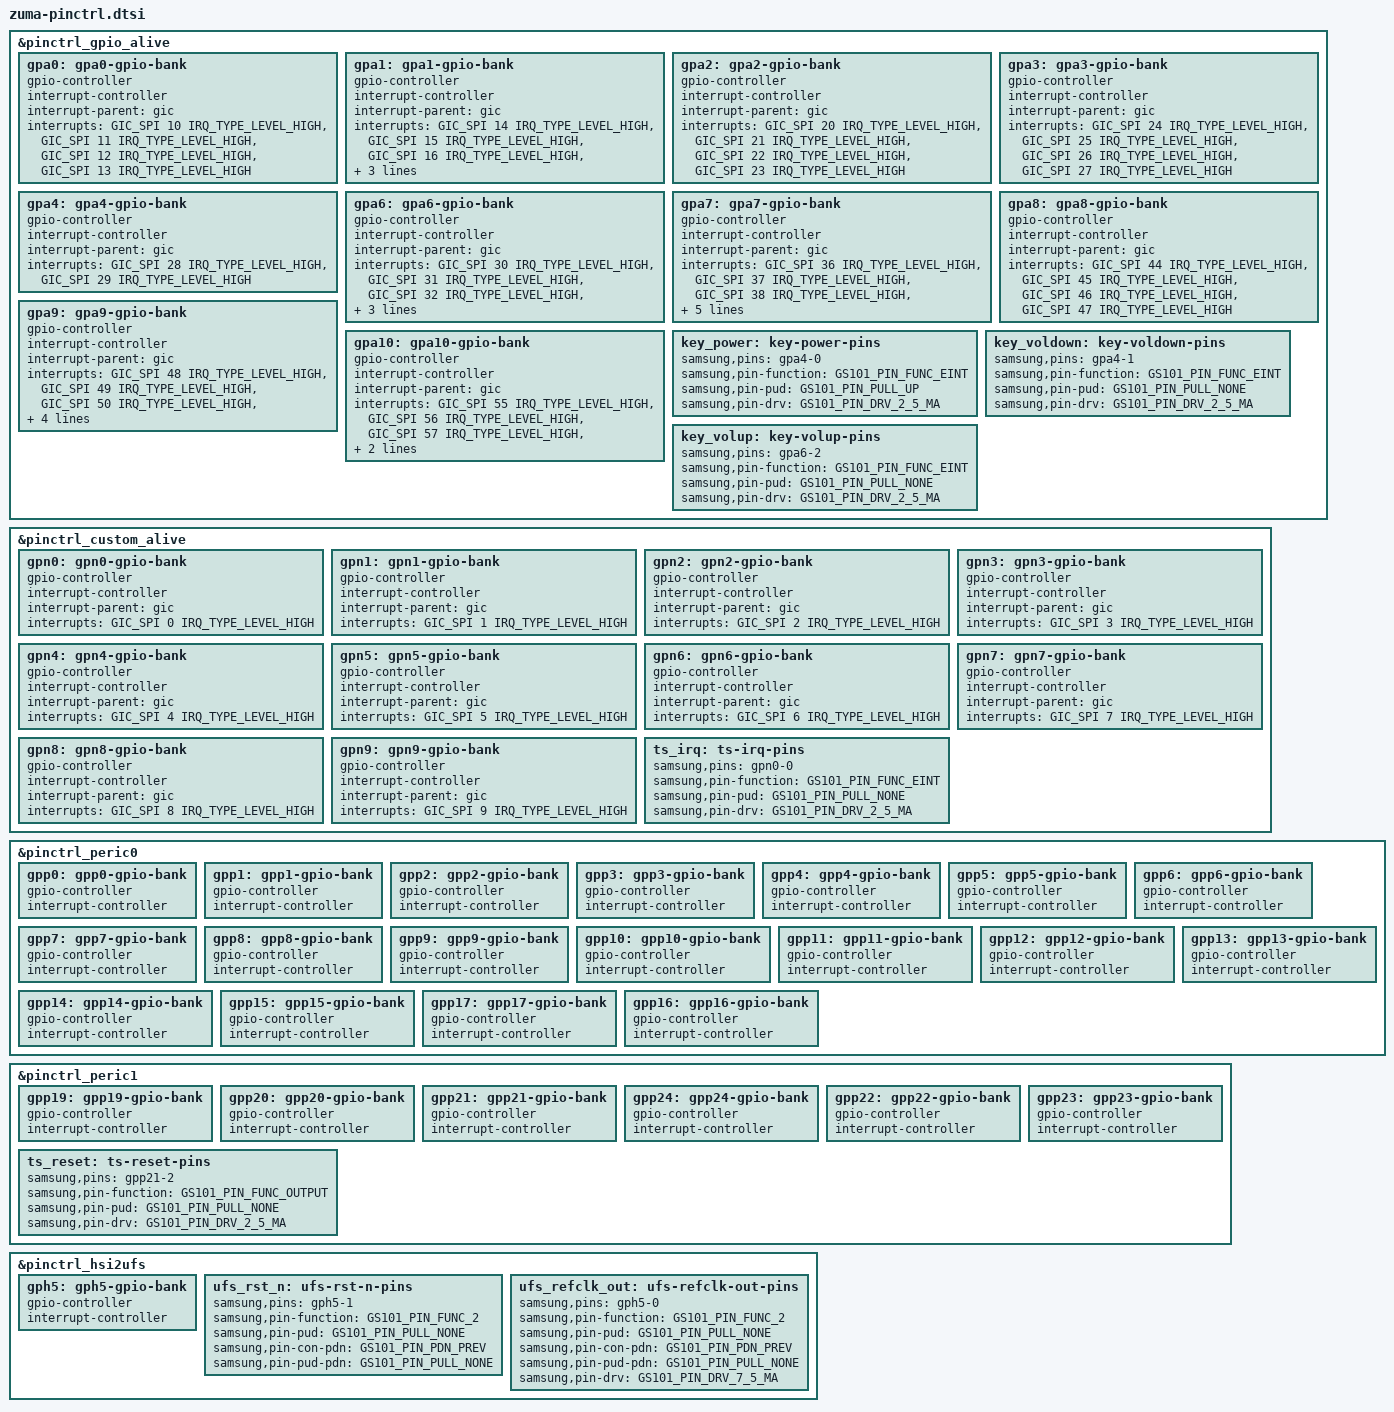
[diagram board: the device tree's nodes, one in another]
// SPDX-License-Identifier: GPL-2.0-only
/*
 * zuma (Tensor G3) pin banks and groups.
 *
 * Copyright 2020-2023 Google LLC
 */

#include "gs101-pinctrl.h"

&pinctrl_gpio_alive {
	gpa0: gpa0-gpio-bank {
		gpio-controller;
		#gpio-cells = <2>;
		interrupt-controller;
		#interrupt-cells = <2>;
		interrupt-parent = <&gic>;
		interrupts = <GIC_SPI 10 IRQ_TYPE_LEVEL_HIGH>,
			     <GIC_SPI 11 IRQ_TYPE_LEVEL_HIGH>,
			     <GIC_SPI 12 IRQ_TYPE_LEVEL_HIGH>,
			     <GIC_SPI 13 IRQ_TYPE_LEVEL_HIGH>;
	};

	gpa1: gpa1-gpio-bank {
		gpio-controller;
		#gpio-cells = <2>;
		interrupt-controller;
		#interrupt-cells = <2>;
		interrupt-parent = <&gic>;
		interrupts = <GIC_SPI 14 IRQ_TYPE_LEVEL_HIGH>,
			     <GIC_SPI 15 IRQ_TYPE_LEVEL_HIGH>,
			     <GIC_SPI 16 IRQ_TYPE_LEVEL_HIGH>,
			     <GIC_SPI 17 IRQ_TYPE_LEVEL_HIGH>,
			     <GIC_SPI 18 IRQ_TYPE_LEVEL_HIGH>,
			     <GIC_SPI 19 IRQ_TYPE_LEVEL_HIGH>;
	};

	gpa2: gpa2-gpio-bank {
		gpio-controller;
		#gpio-cells = <2>;
		interrupt-controller;
		#interrupt-cells = <2>;
		interrupt-parent = <&gic>;
		interrupts = <GIC_SPI 20 IRQ_TYPE_LEVEL_HIGH>,
			     <GIC_SPI 21 IRQ_TYPE_LEVEL_HIGH>,
			     <GIC_SPI 22 IRQ_TYPE_LEVEL_HIGH>,
			     <GIC_SPI 23 IRQ_TYPE_LEVEL_HIGH>;
	};

	gpa3: gpa3-gpio-bank {
		gpio-controller;
		#gpio-cells = <2>;
		interrupt-controller;
		#interrupt-cells = <2>;
		interrupt-parent = <&gic>;
		interrupts = <GIC_SPI 24 IRQ_TYPE_LEVEL_HIGH>,
			     <GIC_SPI 25 IRQ_TYPE_LEVEL_HIGH>,
			     <GIC_SPI 26 IRQ_TYPE_LEVEL_HIGH>,
			     <GIC_SPI 27 IRQ_TYPE_LEVEL_HIGH>;
	};

	gpa4: gpa4-gpio-bank {
		gpio-controller;
		#gpio-cells = <2>;
		interrupt-controller;
		#interrupt-cells = <2>;
		interrupt-parent = <&gic>;
		interrupts = <GIC_SPI 28 IRQ_TYPE_LEVEL_HIGH>,
			     <GIC_SPI 29 IRQ_TYPE_LEVEL_HIGH>;
	};

	gpa6: gpa6-gpio-bank {
		gpio-controller;
		#gpio-cells = <2>;
		interrupt-controller;
		#interrupt-cells = <2>;
		interrupt-parent = <&gic>;
		interrupts = <GIC_SPI 30 IRQ_TYPE_LEVEL_HIGH>,
			     <GIC_SPI 31 IRQ_TYPE_LEVEL_HIGH>,
			     <GIC_SPI 32 IRQ_TYPE_LEVEL_HIGH>,
			     <GIC_SPI 33 IRQ_TYPE_LEVEL_HIGH>,
			     <GIC_SPI 34 IRQ_TYPE_LEVEL_HIGH>,
			     <GIC_SPI 35 IRQ_TYPE_LEVEL_HIGH>;
	};

	gpa7: gpa7-gpio-bank {
		gpio-controller;
		#gpio-cells = <2>;
		interrupt-controller;
		#interrupt-cells = <2>;
		interrupt-parent = <&gic>;
		interrupts = <GIC_SPI 36 IRQ_TYPE_LEVEL_HIGH>,
			     <GIC_SPI 37 IRQ_TYPE_LEVEL_HIGH>,
			     <GIC_SPI 38 IRQ_TYPE_LEVEL_HIGH>,
			     <GIC_SPI 39 IRQ_TYPE_LEVEL_HIGH>,
			     <GIC_SPI 40 IRQ_TYPE_LEVEL_HIGH>,
			     <GIC_SPI 41 IRQ_TYPE_LEVEL_HIGH>,
			     <GIC_SPI 42 IRQ_TYPE_LEVEL_HIGH>,
			     <GIC_SPI 43 IRQ_TYPE_LEVEL_HIGH>;
	};

	gpa8: gpa8-gpio-bank {
		gpio-controller;
		#gpio-cells = <2>;
		interrupt-controller;
		#interrupt-cells = <2>;
		interrupt-parent = <&gic>;
		interrupts = <GIC_SPI 44 IRQ_TYPE_LEVEL_HIGH>,
			     <GIC_SPI 45 IRQ_TYPE_LEVEL_HIGH>,
			     <GIC_SPI 46 IRQ_TYPE_LEVEL_HIGH>,
			     <GIC_SPI 47 IRQ_TYPE_LEVEL_HIGH>;
	};

	gpa9: gpa9-gpio-bank {
		gpio-controller;
		#gpio-cells = <2>;
		interrupt-controller;
		#interrupt-cells = <2>;
		interrupt-parent = <&gic>;
		interrupts = <GIC_SPI 48 IRQ_TYPE_LEVEL_HIGH>,
			     <GIC_SPI 49 IRQ_TYPE_LEVEL_HIGH>,
			     <GIC_SPI 50 IRQ_TYPE_LEVEL_HIGH>,
			     <GIC_SPI 51 IRQ_TYPE_LEVEL_HIGH>,
			     <GIC_SPI 52 IRQ_TYPE_LEVEL_HIGH>,
			     <GIC_SPI 53 IRQ_TYPE_LEVEL_HIGH>,
			     <GIC_SPI 54 IRQ_TYPE_LEVEL_HIGH>;
	};

	gpa10: gpa10-gpio-bank {
		gpio-controller;
		#gpio-cells = <2>;
		interrupt-controller;
		#interrupt-cells = <2>;
		interrupt-parent = <&gic>;
		interrupts = <GIC_SPI 55 IRQ_TYPE_LEVEL_HIGH>,
			     <GIC_SPI 56 IRQ_TYPE_LEVEL_HIGH>,
			     <GIC_SPI 57 IRQ_TYPE_LEVEL_HIGH>,
			     <GIC_SPI 58 IRQ_TYPE_LEVEL_HIGH>,
			     <GIC_SPI 59 IRQ_TYPE_LEVEL_HIGH>;
	};

	key_power: key-power-pins {
		samsung,pins = "gpa4-0";
		samsung,pin-function = <GS101_PIN_FUNC_EINT>;
		samsung,pin-pud = <GS101_PIN_PULL_UP>;
		samsung,pin-drv = <GS101_PIN_DRV_2_5_MA>;
	};

	key_voldown: key-voldown-pins {
		samsung,pins = "gpa4-1";
		samsung,pin-function = <GS101_PIN_FUNC_EINT>;
		samsung,pin-pud = <GS101_PIN_PULL_NONE>;
		samsung,pin-drv = <GS101_PIN_DRV_2_5_MA>;
	};

	key_volup: key-volup-pins {
		samsung,pins = "gpa6-2";
		samsung,pin-function = <GS101_PIN_FUNC_EINT>;
		samsung,pin-pud = <GS101_PIN_PULL_NONE>;
		samsung,pin-drv = <GS101_PIN_DRV_2_5_MA>;
	};
};

&pinctrl_custom_alive {
	gpn0: gpn0-gpio-bank {
		gpio-controller;
		#gpio-cells = <2>;
		interrupt-controller;
		#interrupt-cells = <2>;
		interrupt-parent = <&gic>;
		interrupts = <GIC_SPI 0 IRQ_TYPE_LEVEL_HIGH>;
	};

	gpn1: gpn1-gpio-bank {
		gpio-controller;
		#gpio-cells = <2>;
		interrupt-controller;
		#interrupt-cells = <2>;
		interrupt-parent = <&gic>;
		interrupts = <GIC_SPI 1 IRQ_TYPE_LEVEL_HIGH>;
	};

	gpn2: gpn2-gpio-bank {
		gpio-controller;
		#gpio-cells = <2>;
		interrupt-controller;
		#interrupt-cells = <2>;
		interrupt-parent = <&gic>;
		interrupts = <GIC_SPI 2 IRQ_TYPE_LEVEL_HIGH>;
	};

	gpn3: gpn3-gpio-bank {
		gpio-controller;
		#gpio-cells = <2>;
		interrupt-controller;
		#interrupt-cells = <2>;
		interrupt-parent = <&gic>;
		interrupts = <GIC_SPI 3 IRQ_TYPE_LEVEL_HIGH>;
	};

	gpn4: gpn4-gpio-bank {
		gpio-controller;
		#gpio-cells = <2>;
		interrupt-controller;
		#interrupt-cells = <2>;
		interrupt-parent = <&gic>;
		interrupts = <GIC_SPI 4 IRQ_TYPE_LEVEL_HIGH>;
	};

	gpn5: gpn5-gpio-bank {
		gpio-controller;
		#gpio-cells = <2>;
		interrupt-controller;
		#interrupt-cells = <2>;
		interrupt-parent = <&gic>;
		interrupts = <GIC_SPI 5 IRQ_TYPE_LEVEL_HIGH>;
	};

	gpn6: gpn6-gpio-bank {
		gpio-controller;
		#gpio-cells = <2>;
		interrupt-controller;
		#interrupt-cells = <2>;
		interrupt-parent = <&gic>;
		interrupts = <GIC_SPI 6 IRQ_TYPE_LEVEL_HIGH>;
	};

	gpn7: gpn7-gpio-bank {
		gpio-controller;
		#gpio-cells = <2>;
		interrupt-controller;
		#interrupt-cells = <2>;
		interrupt-parent = <&gic>;
		interrupts = <GIC_SPI 7 IRQ_TYPE_LEVEL_HIGH>;
	};

	gpn8: gpn8-gpio-bank {
		gpio-controller;
		#gpio-cells = <2>;
		interrupt-controller;
		#interrupt-cells = <2>;
		interrupt-parent = <&gic>;
		interrupts = <GIC_SPI 8 IRQ_TYPE_LEVEL_HIGH>;
	};

	gpn9: gpn9-gpio-bank {
		gpio-controller;
		#gpio-cells = <2>;
		interrupt-controller;
		#interrupt-cells = <2>;
		interrupt-parent = <&gic>;
		interrupts = <GIC_SPI 9 IRQ_TYPE_LEVEL_HIGH>;
	};

	ts_irq: ts-irq-pins {
		samsung,pins = "gpn0-0";
		samsung,pin-function = <GS101_PIN_FUNC_EINT>;
		samsung,pin-pud = <GS101_PIN_PULL_NONE>;
		samsung,pin-drv = <GS101_PIN_DRV_2_5_MA>;
	};
};

&pinctrl_peric0 {
	gpp0: gpp0-gpio-bank {
		gpio-controller;
		#gpio-cells = <2>;
		interrupt-controller;
		#interrupt-cells = <2>;
	};

	gpp1: gpp1-gpio-bank {
		gpio-controller;
		#gpio-cells = <2>;
		interrupt-controller;
		#interrupt-cells = <2>;
	};

	gpp2: gpp2-gpio-bank {
		gpio-controller;
		#gpio-cells = <2>;
		interrupt-controller;
		#interrupt-cells = <2>;
	};

	gpp3: gpp3-gpio-bank {
		gpio-controller;
		#gpio-cells = <2>;
		interrupt-controller;
		#interrupt-cells = <2>;
	};

	gpp4: gpp4-gpio-bank {
		gpio-controller;
		#gpio-cells = <2>;
		interrupt-controller;
		#interrupt-cells = <2>;
	};

	gpp5: gpp5-gpio-bank {
		gpio-controller;
		#gpio-cells = <2>;
		interrupt-controller;
		#interrupt-cells = <2>;
	};

	gpp6: gpp6-gpio-bank {
		gpio-controller;
		#gpio-cells = <2>;
		interrupt-controller;
		#interrupt-cells = <2>;
	};

	gpp7: gpp7-gpio-bank {
		gpio-controller;
		#gpio-cells = <2>;
		interrupt-controller;
		#interrupt-cells = <2>;
	};

	gpp8: gpp8-gpio-bank {
		gpio-controller;
		#gpio-cells = <2>;
		interrupt-controller;
		#interrupt-cells = <2>;
	};

	gpp9: gpp9-gpio-bank {
		gpio-controller;
		#gpio-cells = <2>;
		interrupt-controller;
		#interrupt-cells = <2>;
	};

	gpp10: gpp10-gpio-bank {
		gpio-controller;
		#gpio-cells = <2>;
		interrupt-controller;
		#interrupt-cells = <2>;
	};

	gpp11: gpp11-gpio-bank {
		gpio-controller;
		#gpio-cells = <2>;
		interrupt-controller;
		#interrupt-cells = <2>;
	};

	gpp12: gpp12-gpio-bank {
		gpio-controller;
		#gpio-cells = <2>;
		interrupt-controller;
		#interrupt-cells = <2>;
	};

	gpp13: gpp13-gpio-bank {
		gpio-controller;
		#gpio-cells = <2>;
		interrupt-controller;
		#interrupt-cells = <2>;
	};

	gpp14: gpp14-gpio-bank {
		gpio-controller;
		#gpio-cells = <2>;
		interrupt-controller;
		#interrupt-cells = <2>;
	};

	gpp15: gpp15-gpio-bank {
		gpio-controller;
		#gpio-cells = <2>;
		interrupt-controller;
		#interrupt-cells = <2>;
	};

	gpp17: gpp17-gpio-bank {
		gpio-controller;
		#gpio-cells = <2>;
		interrupt-controller;
		#interrupt-cells = <2>;
	};

	gpp16: gpp16-gpio-bank {
		gpio-controller;
		#gpio-cells = <2>;
		interrupt-controller;
		#interrupt-cells = <2>;
	};
};

&pinctrl_peric1 {
	gpp19: gpp19-gpio-bank {
		gpio-controller;
		#gpio-cells = <2>;
		interrupt-controller;
		#interrupt-cells = <2>;
	};

	gpp20: gpp20-gpio-bank {
		gpio-controller;
		#gpio-cells = <2>;
		interrupt-controller;
		#interrupt-cells = <2>;
	};

	gpp21: gpp21-gpio-bank {
		gpio-controller;
		#gpio-cells = <2>;
		interrupt-controller;
		#interrupt-cells = <2>;
	};

	gpp24: gpp24-gpio-bank {
		gpio-controller;
		#gpio-cells = <2>;
		interrupt-controller;
		#interrupt-cells = <2>;
	};

	gpp22: gpp22-gpio-bank {
		gpio-controller;
		#gpio-cells = <2>;
		interrupt-controller;
		#interrupt-cells = <2>;
	};

	gpp23: gpp23-gpio-bank {
		gpio-controller;
		#gpio-cells = <2>;
		interrupt-controller;
		#interrupt-cells = <2>;
	};

	ts_reset: ts-reset-pins {
		samsung,pins = "gpp21-2";
		samsung,pin-function = <GS101_PIN_FUNC_OUTPUT>;
		samsung,pin-pud = <GS101_PIN_PULL_NONE>;
		samsung,pin-drv = <GS101_PIN_DRV_2_5_MA>;
	};
};

&pinctrl_hsi2ufs {
	gph5: gph5-gpio-bank {
		gpio-controller;
		#gpio-cells = <2>;
		interrupt-controller;
		#interrupt-cells = <2>;
	};

	ufs_rst_n: ufs-rst-n-pins {
		samsung,pins = "gph5-1";
		samsung,pin-function = <GS101_PIN_FUNC_2>;
		samsung,pin-pud = <GS101_PIN_PULL_NONE>;
		samsung,pin-con-pdn = <GS101_PIN_PDN_PREV>;
		samsung,pin-pud-pdn = <GS101_PIN_PULL_NONE>;
	};

	ufs_refclk_out: ufs-refclk-out-pins {
		samsung,pins = "gph5-0";
		samsung,pin-function = <GS101_PIN_FUNC_2>;
		samsung,pin-pud = <GS101_PIN_PULL_NONE>;
		samsung,pin-con-pdn = <GS101_PIN_PDN_PREV>;
		samsung,pin-pud-pdn = <GS101_PIN_PULL_NONE>;
		samsung,pin-drv = <GS101_PIN_DRV_7_5_MA>;
	};
};
